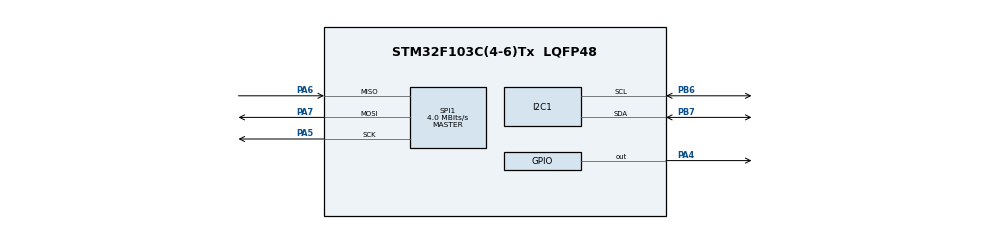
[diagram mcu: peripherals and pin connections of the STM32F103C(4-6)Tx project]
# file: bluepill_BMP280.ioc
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Mcu.Family=STM32F1
Mcu.Name=STM32F103C(4-6)Tx
Mcu.Package=LQFP48
NVIC.PriorityGroup=NVIC_PRIORITYGROUP_4
PA13.Mode=Serial_Wire
PA13.Signal=SYS_JTMS-SWDIO
PA14.Mode=Serial_Wire
PA14.Signal=SYS_JTCK-SWCLK
PA4.Signal=GPIO_Output
PA5.Mode=Full_Duplex_Master
PA5.Signal=SPI1_SCK
PA6.Mode=Full_Duplex_Master
PA6.Signal=SPI1_MISO
PA7.Mode=Full_Duplex_Master
PA7.Signal=SPI1_MOSI
PB6.Mode=I2C
PB6.Signal=I2C1_SCL
PB7.Mode=I2C
PB7.Signal=I2C1_SDA
PD0-OSC_IN.Mode=HSE-External-Oscillator
PD0-OSC_IN.Signal=RCC_OSC_IN
PD1-OSC_OUT.Mode=HSE-External-Oscillator
PD1-OSC_OUT.Signal=RCC_OSC_OUT
ProjectManager.HeapSize=0x200
ProjectManager.StackSize=0x400
ProjectManager.TargetToolchain=STM32CubeIDE
RCC.APB1Freq_Value=8000000
RCC.APB2Freq_Value=8000000
SPI1.CLKPolarity=SPI_POLARITY_HIGH
SPI1.CalculateBaudRate=4.0 MBits/s
SPI1.Direction=SPI_DIRECTION_2LINES
SPI1.Mode=SPI_MODE_MASTER
SPI1.VirtualType=VM_MASTER
board=custom

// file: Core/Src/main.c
/* USER CODE BEGIN Header */
/**
  ******************************************************************************
  * @file           : main.c
  * @brief          : Main program body
  ******************************************************************************
  * @attention
  *
  * Copyright (c) 2023 STMicroelectronics.
  * All rights reserved.
  *
  * This software is licensed under terms that can be found in the LICENSE file
  * in the root directory of this software component.
  * If no LICENSE file comes with this software, it is provided AS-IS.
  *
  ******************************************************************************
  */
/* USER CODE END Header */
#include "main.h"
#include "stdio.h"
/* USER CODE BEGIN Includes */
#include "BMP280.h"
#include "liquidcrystal_i2c.h"
/* USER CODE END Includes */

I2C_HandleTypeDef hi2c1;

SPI_HandleTypeDef hspi1;

/* USER CODE BEGIN PV */
extern float temperature, pressure, altitude, init_height;
/* USER CODE END PV */

void SystemClock_Config(void);
static void MX_GPIO_Init(void);
static void MX_I2C1_Init(void);
static void MX_SPI1_Init(void);

int main(void)
{

  /* MCU Configuration--------------------------------------------------------*/

  /* Reset of all peripherals, Initializes the Flash interface and the Systick. */
  HAL_Init();

  /* Configure the system clock */
  SystemClock_Config();

  /* Initialize all configured peripherals */
  MX_GPIO_Init();
  MX_I2C1_Init();
  MX_SPI1_Init();
  /* USER CODE BEGIN 2 */

  BMP280_init();

  /* USER CODE END 2 */
  HD44780_Init(2);
  HD44780_Clear();
  HD44780_SetCursor(0,0);
  HD44780_PrintStr("HELLO");
  HD44780_SetCursor(10,1);
  HD44780_PrintStr("WORLD");
  HAL_Delay(200);
  /* Infinite loop */
  /* USER CODE BEGIN WHILE */
  char buf1[10],buf2[10];

   while (1)
   {
	  measure();
 	  //BMP280_calc_values();
 	  HAL_Delay(500);
 	  HD44780_SetCursor(0,0);
 	  gcvt(temperature, 10, buf1);
 	  HD44780_Clear();					//converting float to string

 	  HD44780_PrintStr(buf1);			//print temperature values to LCD
 	  HAL_Delay(500);
 	  HD44780_SetCursor(10,1);
 	  gcvt(pressure/4, 10, buf2);

 	  HD44780_PrintStr(buf2);			//print pressure values to LCD

   }
  /* USER CODE END 3 */
}

void SystemClock_Config(void)
{
  RCC_OscInitTypeDef RCC_OscInitStruct = {0};
  RCC_ClkInitTypeDef RCC_ClkInitStruct = {0};

  /** Initializes the RCC Oscillators according to the specified parameters
  * in the RCC_OscInitTypeDef structure.
  */
  RCC_OscInitStruct.OscillatorType = RCC_OSCILLATORTYPE_HSI;
  RCC_OscInitStruct.HSIState = RCC_HSI_ON;
  RCC_OscInitStruct.HSICalibrationValue = RCC_HSICALIBRATION_DEFAULT;
  RCC_OscInitStruct.PLL.PLLState = RCC_PLL_NONE;
  if (HAL_RCC_OscConfig(&RCC_OscInitStruct) != HAL_OK)
  {
    Error_Handler();
  }

  /** Initializes the CPU, AHB and APB buses clocks
  */
  RCC_ClkInitStruct.ClockType = RCC_CLOCKTYPE_HCLK|RCC_CLOCKTYPE_SYSCLK
                              |RCC_CLOCKTYPE_PCLK1|RCC_CLOCKTYPE_PCLK2;
  RCC_ClkInitStruct.SYSCLKSource = RCC_SYSCLKSOURCE_HSI;
  RCC_ClkInitStruct.AHBCLKDivider = RCC_SYSCLK_DIV1;
  RCC_ClkInitStruct.APB1CLKDivider = RCC_HCLK_DIV1;
  RCC_ClkInitStruct.APB2CLKDivider = RCC_HCLK_DIV1;

  if (HAL_RCC_ClockConfig(&RCC_ClkInitStruct, FLASH_LATENCY_0) != HAL_OK)
  {
    Error_Handler();
  }
}

static void MX_I2C1_Init(void)
{

  hi2c1.Instance = I2C1;
  hi2c1.Init.ClockSpeed = 100000;
  hi2c1.Init.DutyCycle = I2C_DUTYCYCLE_2;
  hi2c1.Init.OwnAddress1 = 0;
  hi2c1.Init.AddressingMode = I2C_ADDRESSINGMODE_7BIT;
  hi2c1.Init.DualAddressMode = I2C_DUALADDRESS_DISABLE;
  hi2c1.Init.OwnAddress2 = 0;
  hi2c1.Init.GeneralCallMode = I2C_GENERALCALL_DISABLE;
  hi2c1.Init.NoStretchMode = I2C_NOSTRETCH_DISABLE;
  if (HAL_I2C_Init(&hi2c1) != HAL_OK)
  {
    Error_Handler();
  }

}

static void MX_SPI1_Init(void)
{

  /* SPI1 parameter configuration*/
  hspi1.Instance = SPI1;
  hspi1.Init.Mode = SPI_MODE_MASTER;
  hspi1.Init.Direction = SPI_DIRECTION_2LINES;
  hspi1.Init.DataSize = SPI_DATASIZE_8BIT;
  hspi1.Init.CLKPolarity = SPI_POLARITY_HIGH;
  hspi1.Init.CLKPhase = SPI_PHASE_1EDGE;
  hspi1.Init.NSS = SPI_NSS_SOFT;
  hspi1.Init.BaudRatePrescaler = SPI_BAUDRATEPRESCALER_2;
  hspi1.Init.FirstBit = SPI_FIRSTBIT_MSB;
  hspi1.Init.TIMode = SPI_TIMODE_DISABLE;
  hspi1.Init.CRCCalculation = SPI_CRCCALCULATION_DISABLE;
  hspi1.Init.CRCPolynomial = 10;
  if (HAL_SPI_Init(&hspi1) != HAL_OK)
  {
    Error_Handler();
  }

}

static void MX_GPIO_Init(void)
{
  GPIO_InitTypeDef GPIO_InitStruct = {0};

  /* GPIO Ports Clock Enable */
  __HAL_RCC_GPIOD_CLK_ENABLE();
  __HAL_RCC_GPIOA_CLK_ENABLE();
  __HAL_RCC_GPIOB_CLK_ENABLE();

  /*Configure GPIO pin Output Level */
  HAL_GPIO_WritePin(GPIOA, GPIO_PIN_4, GPIO_PIN_RESET);

  /*Configure GPIO pin : PA4 */
  GPIO_InitStruct.Pin = GPIO_PIN_4;
  GPIO_InitStruct.Mode = GPIO_MODE_OUTPUT_PP;
  GPIO_InitStruct.Pull = GPIO_NOPULL;
  GPIO_InitStruct.Speed = GPIO_SPEED_FREQ_LOW;
  HAL_GPIO_Init(GPIOA, &GPIO_InitStruct);

}

void Error_Handler(void)
{
  __disable_irq();
  while (1)
  {
  }
}
